# RP2350 register map
Vendor: Raspberry Pi; Series: RP; File version: 0.1
CPU: CM33 r1p0, little endian, MPU, FPU, DSP, VTOR, 4 interrupt priority bits, 52 interrupts, 8 SAU regions
Registers are 32-bit, read-write, reset 0x0 unless marked. A register's access mark holds for its fields unless they carry their own. Offsets are from the block's base; [hi:lo] are bit positions; {n}, {i} and the like mark numbered series; 'fields as' and 'values as' point back to an identical list.

## PWM — Simple PWM
Base 0x400A8000
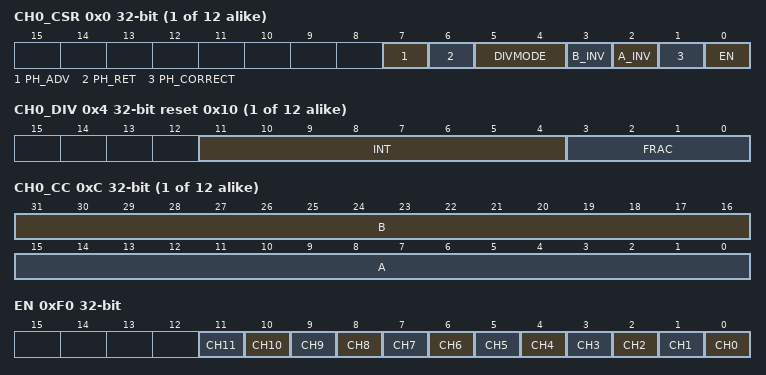
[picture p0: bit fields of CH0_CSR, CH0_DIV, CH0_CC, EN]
{0x0+0x14*i} CH{i}_CSR (i=0..11) — Control and status register
  [7] PH_ADV wo — Advance the phase of the counter by 1 count, while it is running. Self-clearing. Write a 1, and poll until low. Counter must be running at less than full speed (div_int + div_frac / 16 > 1)
  [6] PH_RET wo — Retard the phase of the counter by 1 count, while it is running. Self-clearing. Write a 1, and poll until low. Counter must be running.
  [5:4] DIVMODE — Pre-defined description
    0=div (Free-running counting at rate dictated by fractional divider); 1=level (Fractional divider operation is gated by the PWM B pin.); 2=rise (Counter advances with each rising edge of the PWM B pin.); 3=fall (Counter advances with each falling edge of the PWM B pin.)
  [3] B_INV — Invert output B
  [2] A_INV — Invert output A
  [1] PH_CORRECT — 1: Enable phase-correct modulation. 0: Trailing-edge
  [0] EN — Enable the PWM channel.
{0x4+0x14*i} CH{i}_DIV reset 0x10 (i=0..11) — INT and FRAC form a fixed-point fractional number. Counting rate is system clock frequency divided by this number. Fractional division uses simple 1st-order sigma-delta.
  [11:4] INT — Pre-defined description
  [3:0] FRAC — Pre-defined description
{0x8+0x14*i} CH{i}_CTR (i=0..11) — Direct access to the PWM counter
  [15:0] CH{i}_CTR — Pre-defined description
{0xC+0x14*i} CH{i}_CC (i=0..11) — Counter compare values
  [31:16] B — Pre-defined description
  [15:0] A — Pre-defined description
{0x10+0x14*i} CH{i}_TOP reset 0xFFFF (i=0..11) — Counter wrap value
  [15:0] CH{i}_TOP — Pre-defined description
0xF0 EN — This register aliases the CSR_EN bits for all channels. Writing to this register allows multiple channels to be enabled or disabled simultaneously, so they can run in perfect sync. For each channel, there is only one physical EN register bit, which can be accessed through here or CHx_CSR.
  [n] CH{n} (n=0..11) — Pre-defined description
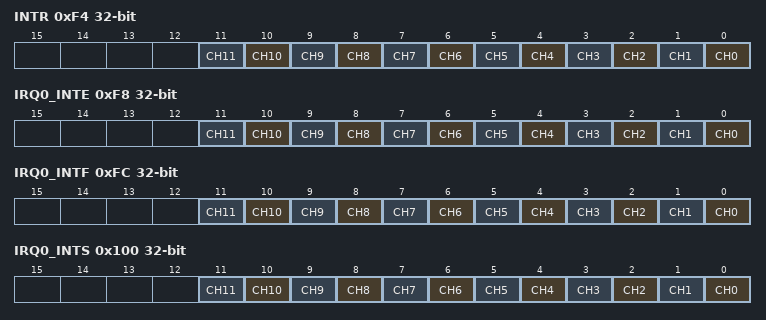
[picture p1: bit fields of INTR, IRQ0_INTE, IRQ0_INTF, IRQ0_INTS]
0xF4 INTR — Raw Interrupts
  [n] CH{n} write-1-clears (n=0..11) — Pre-defined description
0xF8 IRQ0_INTE — Interrupt Enable for irq0
  [n] CH{n} (n=0..11) — Pre-defined description
0xFC IRQ0_INTF — Interrupt Force for irq0
  [n] CH{n} (n=0..11) — Pre-defined description
0x100 IRQ0_INTS — Interrupt status after masking & forcing for irq0
  [n] CH{n} ro (n=0..11) — Pre-defined description
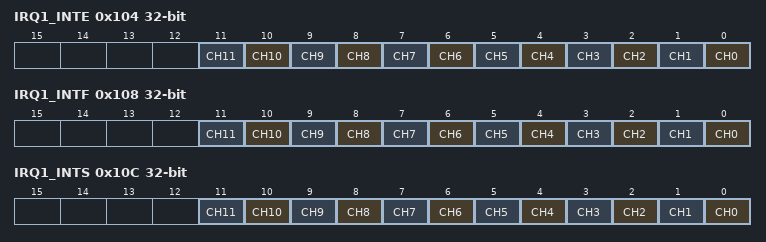
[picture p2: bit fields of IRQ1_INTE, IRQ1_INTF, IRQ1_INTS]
0x104 IRQ1_INTE — Interrupt Enable for irq1
  [n] CH{n} (n=0..11) — Pre-defined description
0x108 IRQ1_INTF — Interrupt Force for irq1
  [n] CH{n} (n=0..11) — Pre-defined description
0x10C IRQ1_INTS — Interrupt status after masking & forcing for irq1
  [n] CH{n} ro (n=0..11) — Pre-defined description

## ADC — Control and data interface to SAR ADC
Base 0x400A0000
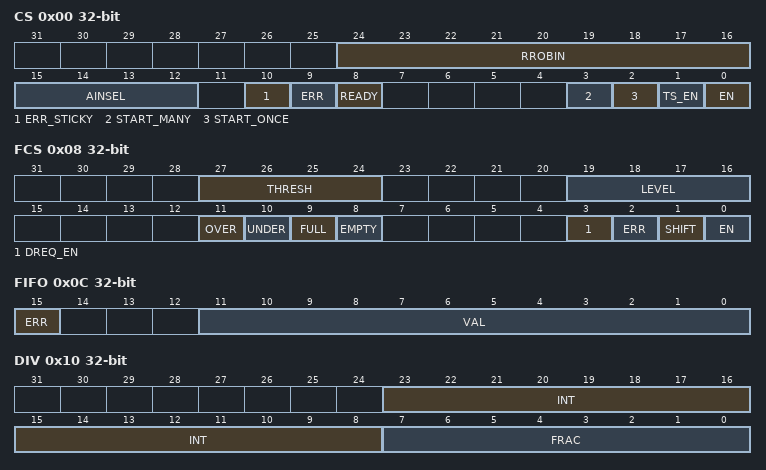
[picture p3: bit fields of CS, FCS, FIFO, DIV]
0x00 CS — ADC Control and Status
  [24:16] RROBIN — Round-robin sampling. 1 bit per channel. Set all bits to 0 to disable. Otherwise, the ADC will cycle through each enabled channel in a round-robin fashion. The first channel to be sampled will be the one currently indicated by AINSEL. AINSEL will be updated after each conversion with the newly-selected channel.
  [15:12] AINSEL — Select analog mux input. Updated automatically in round-robin mode. This is corrected for the package option so only ADC channels which are bonded are available, and in the correct order
  [10] ERR_STICKY write-1-clears — Some past ADC conversion encountered an error. Write 1 to clear.
  [9] ERR ro — The most recent ADC conversion encountered an error; result is undefined or noisy.
  [8] READY ro — 1 if the ADC is ready to start a new conversion. Implies any previous conversion has completed. 0 whilst conversion in progress.
  [3] START_MANY — Continuously perform conversions whilst this bit is 1. A new conversion will start immediately after the previous finishes.
  [2] START_ONCE wo — Start a single conversion. Self-clearing. Ignored if start_many is asserted.
  [1] TS_EN — Power on temperature sensor. 1 - enabled. 0 - disabled.
  [0] EN — Power on ADC and enable its clock. 1 - enabled. 0 - disabled.
0x04 RESULT — Result of most recent ADC conversion
  [11:0] RESULT ro — Pre-defined description
0x08 FCS — FIFO control and status
  [27:24] THRESH — DREQ/IRQ asserted when level >= threshold
  [19:16] LEVEL ro — The number of conversion results currently waiting in the FIFO
  [11] OVER write-1-clears — 1 if the FIFO has been overflowed. Write 1 to clear.
  [10] UNDER write-1-clears — 1 if the FIFO has been underflowed. Write 1 to clear.
  [9] FULL ro — Pre-defined description
  [8] EMPTY ro — Pre-defined description
  [3] DREQ_EN — If 1: assert DMA requests when FIFO contains data
  [2] ERR — If 1: conversion error bit appears in the FIFO alongside the result
  [1] SHIFT — If 1: FIFO results are right-shifted to be one byte in size. Enables DMA to byte buffers.
  [0] EN — If 1: write result to the FIFO after each conversion.
0x0C FIFO — Conversion result FIFO
  [15] ERR ro read-modifies — 1 if this particular sample experienced a conversion error. Remains in the same location if the sample is shifted.
  [11:0] VAL ro read-modifies — Pre-defined description
0x10 DIV — Clock divider. If non-zero, CS_START_MANY will start conversions at regular intervals rather than back-to-back. The divider is reset when either of these fields are written. Total period is 1 + INT + FRAC / 256
  [23:8] INT — Integer part of clock divisor.
  [7:0] FRAC — Fractional part of clock divisor. First-order delta-sigma.
0x14 INTR — Raw Interrupts
  [0] FIFO ro — Triggered when the sample FIFO reaches a certain level. This level can be programmed via the FCS_THRESH field.
0x18 INTE — Interrupt Enable
  [0] FIFO — Triggered when the sample FIFO reaches a certain level. This level can be programmed via the FCS_THRESH field.
0x1C INTF — Interrupt Force
  fields as INTE
0x20 INTS — Interrupt status after masking & forcing
  fields as INTR
